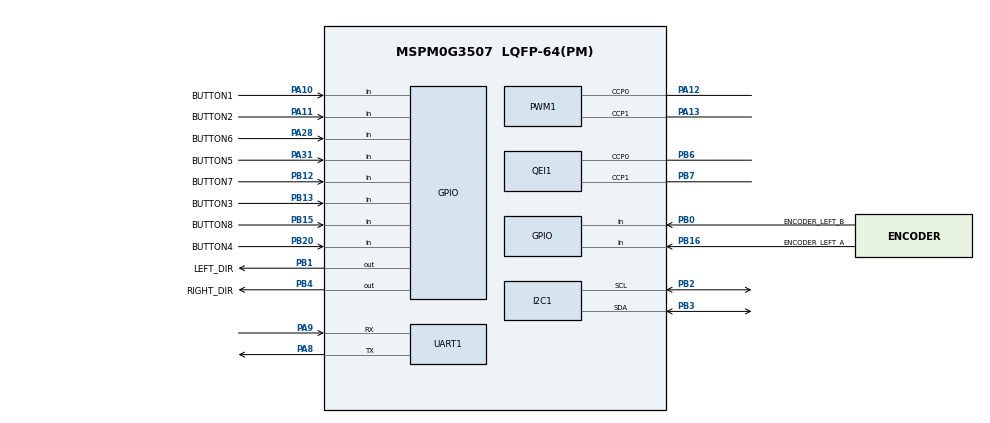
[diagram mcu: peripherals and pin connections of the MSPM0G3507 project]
/**
 * LP-MSPM0G3507 hardware configuration for mspm0dache.
 *
 * Rear-drive differential chassis:
 * - right motor: PA12 PWM, PB4 DIR
 * - left motor:  PA13 PWM, PB1 DIR
 * - right encoder: PB6/PB7 hardware QEI (J2 / BP13-BP14)
 * - left encoder:  PB16/PB0 GPIO quadrature (J2 / BP11-BP12)
 * - Button X8 panel: K1-K8 on PA10, PA11, PB13, PB20, PA31, PA28,
 *   PB12 and PB15; all active low with internal pull-ups
 * - JDY-31 Bluetooth UART temporarily disabled
 * - Hiwonder 8-channel line sensor I2C: PB2 SCL / PB3 SDA, 100 kHz
 * - MC02 supervisor link: UART1 PA8 TX / PA9 RX, 115200 8N1
 */
//@cliArgs --device "MSPM0G350X" --package "LQFP-64(PM)" --part "Default"
//@v2CliArgs --device "MSPM0G3507" --package "LQFP-64(PM)"
// @cliArgs --board /ti/boards/LP_MSPM0G3507 --rtos nortos

const Board  = scripting.addModule("/ti/driverlib/Board", {}, false);
const SYSCTL = scripting.addModule("/ti/driverlib/SYSCTL", {}, false);
const GPIO   = scripting.addModule("/ti/driverlib/GPIO", {}, false);
const PWM    = scripting.addModule("/ti/driverlib/PWM", {}, false);
const QEI    = scripting.addModule("/ti/driverlib/QEI", {}, false);
const I2C    = scripting.addModule("/ti/driverlib/I2C", {}, false);
const UART   = scripting.addModule("/ti/driverlib/UART", {}, false);

Board.configureUnused = false;
SYSCTL.forceDefaultClkConfig = true;
SYSCTL.clockTreeEn = true;

/* DRV8701E EN/PWM inputs, 20 kHz, both disabled at reset. */
const PWM1 = PWM.addInstance();
PWM1.$name = "MOTOR_PWM";
PWM1.timerCount = 1600;
PWM1.peripheral.$assign = "TIMG0";
PWM1.peripheral.ccp0Pin.$assign = "PA12";
PWM1.peripheral.ccp1Pin.$assign = "PA13";
PWM1.PWM_CHANNEL_0.$name = "RIGHT_ENA";
PWM1.PWM_CHANNEL_0.dutyCycle = 0;
PWM1.PWM_CHANNEL_1.$name = "LEFT_ENB";
PWM1.PWM_CHANNEL_1.dutyCycle = 0;

/* Right encoder uses adjacent BoosterPack pins J2 / BP13-BP14. */
const QEI1 = QEI.addInstance();
QEI1.$name = "QEI_RIGHT";
QEI1.peripheral.$assign = "TIMG8";
QEI1.peripheral.ccp0Pin.$assign = "PB6";
QEI1.peripheral.ccp1Pin.$assign = "PB7";

/* DRV8701E PH/DIR outputs. */
const GPIO1 = GPIO.addInstance();
GPIO1.$name = "GPIO_MOTOR";
GPIO1.associatedPins.create(2);
GPIO1.associatedPins[0].$name = "RIGHT_DIR";
GPIO1.associatedPins[0].initialValue = "CLEARED";
GPIO1.associatedPins[0].pin.$assign = "PB4";
GPIO1.associatedPins[1].$name = "LEFT_DIR";
GPIO1.associatedPins[1].initialValue = "CLEARED";
GPIO1.associatedPins[1].pin.$assign = "PB1";

/* Left encoder uses adjacent J2 / BP11-BP12 pins and GPIO decoding. */
const GPIO2 = GPIO.addInstance();
GPIO2.$name = "GPIO_ENCODER_LEFT";
GPIO2.associatedPins.create(2);
GPIO2.associatedPins[0].$name = "ENCODER_LEFT_A";
GPIO2.associatedPins[0].direction = "INPUT";
GPIO2.associatedPins[0].interruptEn = true;
GPIO2.associatedPins[0].polarity = "RISE_FALL";
GPIO2.associatedPins[0].pin.$assign = "PB16";
GPIO2.associatedPins[1].$name = "ENCODER_LEFT_B";
GPIO2.associatedPins[1].direction = "INPUT";
GPIO2.associatedPins[1].interruptEn = true;
GPIO2.associatedPins[1].polarity = "RISE_FALL";
GPIO2.associatedPins[1].pin.$assign = "PB0";

/* Button X8 panel: polled every 10 ms, active low. */
const GPIO3 = GPIO.addInstance();
GPIO3.$name = "GPIO_BUTTON_PANEL_A";
GPIO3.associatedPins.create(4);
GPIO3.associatedPins[0].$name = "BUTTON1";
GPIO3.associatedPins[0].direction = "INPUT";
GPIO3.associatedPins[0].internalResistor = "PULL_UP";
GPIO3.associatedPins[0].pin.$assign = "PA10";
GPIO3.associatedPins[1].$name = "BUTTON2";
GPIO3.associatedPins[1].direction = "INPUT";
GPIO3.associatedPins[1].internalResistor = "PULL_UP";
GPIO3.associatedPins[1].pin.$assign = "PA11";
GPIO3.associatedPins[2].$name = "BUTTON5";
GPIO3.associatedPins[2].direction = "INPUT";
GPIO3.associatedPins[2].internalResistor = "PULL_UP";
GPIO3.associatedPins[2].pin.$assign = "PA31";
GPIO3.associatedPins[3].$name = "BUTTON6";
GPIO3.associatedPins[3].direction = "INPUT";
GPIO3.associatedPins[3].internalResistor = "PULL_UP";
GPIO3.associatedPins[3].pin.$assign = "PA28";

const GPIO4 = GPIO.addInstance();
GPIO4.$name = "GPIO_BUTTON_PANEL_B";
GPIO4.associatedPins.create(4);
GPIO4.associatedPins[0].$name = "BUTTON3";
GPIO4.associatedPins[0].direction = "INPUT";
GPIO4.associatedPins[0].internalResistor = "PULL_UP";
GPIO4.associatedPins[0].pin.$assign = "PB13";
GPIO4.associatedPins[1].$name = "BUTTON4";
GPIO4.associatedPins[1].direction = "INPUT";
GPIO4.associatedPins[1].internalResistor = "PULL_UP";
GPIO4.associatedPins[1].pin.$assign = "PB20";
GPIO4.associatedPins[2].$name = "BUTTON7";
GPIO4.associatedPins[2].direction = "INPUT";
GPIO4.associatedPins[2].internalResistor = "PULL_UP";
GPIO4.associatedPins[2].pin.$assign = "PB12";
GPIO4.associatedPins[3].$name = "BUTTON8";
GPIO4.associatedPins[3].direction = "INPUT";
GPIO4.associatedPins[3].internalResistor = "PULL_UP";
GPIO4.associatedPins[3].pin.$assign = "PB15";

/* Hiwonder LineFollower_8CH V1.0, fixed 7-bit address 0x5D. */
const I2C1 = I2C.addInstance();
I2C1.$name = "LINE_SENSOR_I2C";
I2C1.basicEnableController = true;
I2C1.basicControllerBusSpeed = 100000;
I2C1.peripheral.$assign = "I2C1";
I2C1.peripheral.sclPin.$assign = "PB2";
I2C1.peripheral.sdaPin.$assign = "PB3";

/* DM-MC-Board02 supervisor link, 3.3 V TTL, no flow control. */
const UART1 = UART.addInstance();
UART1.$name = "MC02_UART";
UART1.targetBaudRate = 115200;
UART1.enableFIFO = true;
UART1.rxFifoThreshold = "DL_UART_RX_FIFO_LEVEL_ONE_ENTRY";
UART1.enabledInterrupts = ["RX"];
UART1.peripheral.$assign = "UART1";
UART1.peripheral.rxPin.$assign = "PA9";
UART1.peripheral.txPin.$assign = "PA8";
